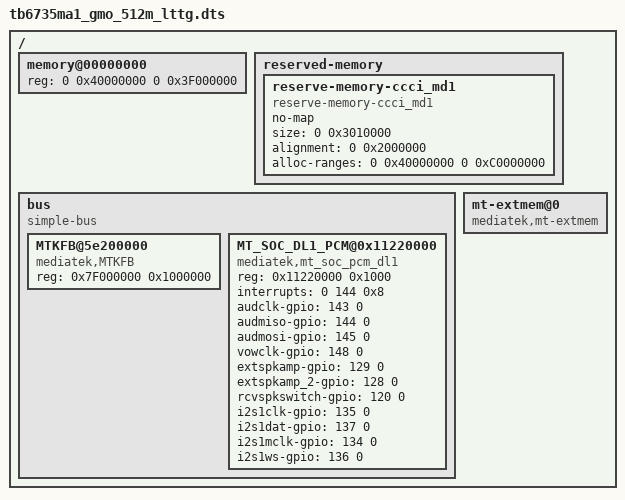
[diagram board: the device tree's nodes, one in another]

/dts-v1/;

/include/ "mt6735m.dtsi"

/ {
  memory@00000000 {
		device_type = "memory";
		reg = <0 0x40000000 0 0x3F000000>;
	};
reserved-memory {
		#address-cells = <2>;
		#size-cells = <2>;
		ranges;

		reserve-memory-ccci_md1 {
			compatible = "reserve-memory-ccci_md1";
			no-map;
			size = <0 0x3010000>; // md_size+smem_size
			alignment = <0 0x2000000>;
			alloc-ranges = <0 0x40000000 0 0xC0000000>;
		};
	};
	bus {
		compatible = "simple-bus";
		#address-cells = <1>;
		#size-cells = <1>;
		ranges = <0 0 0 0xffffffff>;

		MTKFB@5e200000 {
			compatible = "mediatek,MTKFB";
			reg = <0x7F000000 0x1000000>;
		};
                MT_SOC_DL1_PCM@0x11220000 {
			compatible = "mediatek,mt_soc_pcm_dl1";
			reg = <0x11220000 0x1000>;
			interrupts = <0 144 0x8>;
			audclk-gpio = <143 0>;
			audmiso-gpio = <144 0>;
			audmosi-gpio = <145 0>;
			vowclk-gpio = <148 0>;
			extspkamp-gpio = <129 0>;
			extspkamp_2-gpio = <128 0>;
			rcvspkswitch-gpio = <120 0>;						
			i2s1clk-gpio = <135 0>;
			i2s1dat-gpio = <137 0>;
			i2s1mclk-gpio = <134 0>;
			i2s1ws-gpio = <136 0>;
		};


  };
	mt-extmem@0 {
		compatible = "mediatek,mt-extmem";
	};
};
